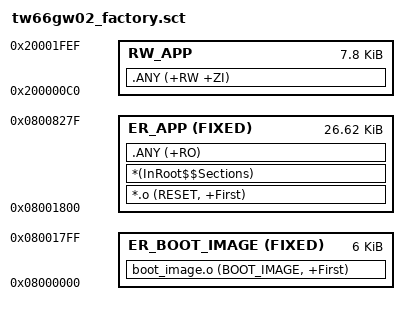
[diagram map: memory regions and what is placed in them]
; Complete factory image: embedded bootloader plus relocated application.
LR_FACTORY 0x08000000 0x00008400
{
  ER_BOOT_IMAGE 0x08000000 FIXED 0x00001800
  {
    boot_image.o (BOOT_IMAGE, +First)
  }
  ER_APP 0x08001800 FIXED 0x00006A80
  {
    *.o (RESET, +First)
    *(InRoot$$Sections)
    .ANY (+RO)
  }
  RW_APP 0x200000C0 0x00001F30
  {
    .ANY (+RW +ZI)
  }
}
